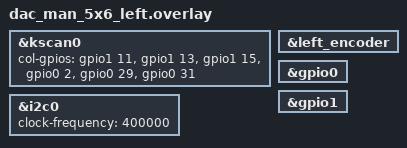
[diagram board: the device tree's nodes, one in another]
#include "dac_man_5x6.dtsi"

&kscan0 {
    col-gpios
        = <&gpio1 11 GPIO_ACTIVE_HIGH>
        , <&gpio1 13 GPIO_ACTIVE_HIGH>
        , <&gpio1 15 GPIO_ACTIVE_HIGH>
        , <&gpio0 2  GPIO_ACTIVE_HIGH>
        , <&gpio0 29 GPIO_ACTIVE_HIGH>
        , <&gpio0 31 GPIO_ACTIVE_HIGH>
        ;
};

&left_encoder {
    status = "okay";
};

&gpio0 {
    status = "okay";
};

&gpio1 {
    status = "okay";
};

&i2c0 {
    status = "okay";
    clock-frequency = <400000>;
};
